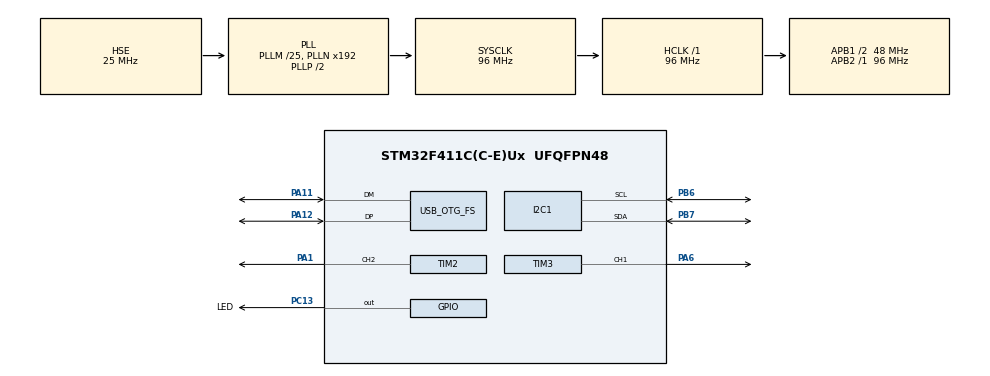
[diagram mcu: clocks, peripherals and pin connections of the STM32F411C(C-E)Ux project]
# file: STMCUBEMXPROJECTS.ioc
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Mcu.Family=STM32F4
Mcu.Name=STM32F411C(C-E)Ux
Mcu.Package=UFQFPN48
NVIC.OTG_FS_IRQn=true\:0\:0\:false\:false\:true\:false\:true\:true
NVIC.PriorityGroup=NVIC_PRIORITYGROUP_4
PA1.Signal=S_TIM2_CH2
PA11.Mode=Device_Only
PA11.Signal=USB_OTG_FS_DM
PA12.Mode=Device_Only
PA12.Signal=USB_OTG_FS_DP
PA13.Mode=Serial_Wire
PA13.Signal=SYS_JTMS-SWDIO
PA14.Mode=Serial_Wire
PA14.Signal=SYS_JTCK-SWCLK
PA6.Signal=S_TIM3_CH1
PB6.Mode=I2C
PB6.Signal=I2C1_SCL
PB7.Mode=I2C
PB7.Signal=I2C1_SDA
PC13-ANTI_TAMP.GPIO_Label=LED
PC13-ANTI_TAMP.Signal=GPIO_Output
PH0\ -\ OSC_IN.Mode=HSE-External-Oscillator
PH0\ -\ OSC_IN.Signal=RCC_OSC_IN
PH1\ -\ OSC_OUT.Mode=HSE-External-Oscillator
PH1\ -\ OSC_OUT.Signal=RCC_OSC_OUT
ProjectManager.HeapSize=0x200
ProjectManager.StackSize=0x400
ProjectManager.TargetToolchain=CMake
RCC.48MHZClocksFreq_Value=48000000
RCC.AHBFreq_Value=96000000
RCC.APB1CLKDivider=RCC_HCLK_DIV2
RCC.APB1Freq_Value=48000000
RCC.APB1TimFreq_Value=96000000
RCC.APB2Freq_Value=96000000
RCC.APB2TimFreq_Value=96000000
RCC.CortexFreq_Value=96000000
RCC.HCLKFreq_Value=96000000
RCC.HSE_VALUE=25000000
RCC.HSI_VALUE=16000000
RCC.LSE_VALUE=32768
RCC.PLLM=25
RCC.SYSCLKFreq_VALUE=96000000
RCC.SYSCLKSource=RCC_SYSCLKSOURCE_PLLCLK
RCC.VCOOutputFreq_Value=192000000
SH.S_TIM2_CH2.0=TIM2_CH2,PWM Generation2 CH2
SH.S_TIM3_CH1.0=TIM3_CH1,PWM Generation1 CH1
TIM2.Channel-PWM\ Generation2\ CH2=TIM_CHANNEL_2
TIM2.Period=19999
TIM2.Prescaler=95
TIM2.Pulse-PWM\ Generation2\ CH2=1500
TIM3.Channel-PWM\ Generation1\ CH1=TIM_CHANNEL_1
TIM3.Period=999
TIM3.Prescaler=95
TIM3.Pulse-PWM\ Generation1\ CH1=250
USB_DEVICE.CLASS_NAME_FS=CDC
USB_DEVICE.VirtualMode=Cdc
USB_DEVICE.VirtualModeFS=Cdc_FS
USB_OTG_FS.VirtualMode=Device_Only
VP_TIM2_VS_ClockSourceINT.Mode=Internal
VP_TIM3_VS_ClockSourceINT.Mode=Internal
VP_USB_DEVICE_VS_USB_DEVICE_CDC_FS.Mode=CDC_FS
board=custom

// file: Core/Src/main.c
/* USER CODE BEGIN Header */
/**
 ******************************************************************************
 * @file           : main.c
 * @brief          : Main program body
 ******************************************************************************
 * @attention
 *
 * Copyright (c) 2026 STMicroelectronics.
 * All rights reserved.
 *
 * This software is licensed under terms that can be found in the LICENSE file
 * in the root directory of this software component.
 * If no LICENSE file comes with this software, it is provided AS-IS.
 *
 ******************************************************************************
 */
/* USER CODE END Header */
#include "main.h"
#include "usb_device.h"

/* USER CODE BEGIN Includes */
#include "app.h"

/* USER CODE END Includes */

I2C_HandleTypeDef hi2c1;

TIM_HandleTypeDef htim2;
TIM_HandleTypeDef htim3;

void SystemClock_Config(void);
static void MX_GPIO_Init(void);
static void MX_TIM3_Init(void);
static void MX_TIM2_Init(void);
static void MX_I2C1_Init(void);

int main(void)
{

  /* MCU Configuration--------------------------------------------------------*/

  /* Reset of all peripherals, Initializes the Flash interface and the Systick. */
  HAL_Init();

  /* Configure the system clock */
  SystemClock_Config();

  /* Initialize all configured peripherals */
  MX_GPIO_Init();
  MX_USB_DEVICE_Init();
  MX_TIM3_Init();
  MX_TIM2_Init();
  MX_I2C1_Init();
  /* USER CODE BEGIN 2 */

  app_setup();

  /* USER CODE END 2 */

  /* Infinite loop */
  while (1) {

    /* USER CODE BEGIN 3 */

    app_loop();
  }
  /* USER CODE END 3 */
}

void SystemClock_Config(void)
{
  RCC_OscInitTypeDef RCC_OscInitStruct = {0};
  RCC_ClkInitTypeDef RCC_ClkInitStruct = {0};

  /** Configure the main internal regulator output voltage
  */
  __HAL_RCC_PWR_CLK_ENABLE();
  __HAL_PWR_VOLTAGESCALING_CONFIG(PWR_REGULATOR_VOLTAGE_SCALE1);

  /** Initializes the RCC Oscillators according to the specified parameters
  * in the RCC_OscInitTypeDef structure.
  */
  RCC_OscInitStruct.OscillatorType = RCC_OSCILLATORTYPE_HSE;
  RCC_OscInitStruct.HSEState = RCC_HSE_ON;
  RCC_OscInitStruct.PLL.PLLState = RCC_PLL_ON;
  RCC_OscInitStruct.PLL.PLLSource = RCC_PLLSOURCE_HSE;
  RCC_OscInitStruct.PLL.PLLM = 25;
  RCC_OscInitStruct.PLL.PLLN = 192;
  RCC_OscInitStruct.PLL.PLLP = RCC_PLLP_DIV2;
  RCC_OscInitStruct.PLL.PLLQ = 4;
  if (HAL_RCC_OscConfig(&RCC_OscInitStruct) != HAL_OK)
  {
    Error_Handler();
  }

  /** Initializes the CPU, AHB and APB buses clocks
  */
  RCC_ClkInitStruct.ClockType = RCC_CLOCKTYPE_HCLK|RCC_CLOCKTYPE_SYSCLK
                              |RCC_CLOCKTYPE_PCLK1|RCC_CLOCKTYPE_PCLK2;
  RCC_ClkInitStruct.SYSCLKSource = RCC_SYSCLKSOURCE_PLLCLK;
  RCC_ClkInitStruct.AHBCLKDivider = RCC_SYSCLK_DIV1;
  RCC_ClkInitStruct.APB1CLKDivider = RCC_HCLK_DIV2;
  RCC_ClkInitStruct.APB2CLKDivider = RCC_HCLK_DIV1;

  if (HAL_RCC_ClockConfig(&RCC_ClkInitStruct, FLASH_LATENCY_3) != HAL_OK)
  {
    Error_Handler();
  }
}

static void MX_I2C1_Init(void)
{

  hi2c1.Instance = I2C1;
  hi2c1.Init.ClockSpeed = 100000;
  hi2c1.Init.DutyCycle = I2C_DUTYCYCLE_2;
  hi2c1.Init.OwnAddress1 = 0;
  hi2c1.Init.AddressingMode = I2C_ADDRESSINGMODE_7BIT;
  hi2c1.Init.DualAddressMode = I2C_DUALADDRESS_DISABLE;
  hi2c1.Init.OwnAddress2 = 0;
  hi2c1.Init.GeneralCallMode = I2C_GENERALCALL_DISABLE;
  hi2c1.Init.NoStretchMode = I2C_NOSTRETCH_DISABLE;
  if (HAL_I2C_Init(&hi2c1) != HAL_OK)
  {
    Error_Handler();
  }

}

static void MX_TIM2_Init(void)
{

  TIM_ClockConfigTypeDef sClockSourceConfig = {0};
  TIM_MasterConfigTypeDef sMasterConfig = {0};
  TIM_OC_InitTypeDef sConfigOC = {0};

  htim2.Instance = TIM2;
  htim2.Init.Prescaler = 95;
  htim2.Init.CounterMode = TIM_COUNTERMODE_UP;
  htim2.Init.Period = 19999;
  htim2.Init.ClockDivision = TIM_CLOCKDIVISION_DIV1;
  htim2.Init.AutoReloadPreload = TIM_AUTORELOAD_PRELOAD_DISABLE;
  if (HAL_TIM_Base_Init(&htim2) != HAL_OK)
  {
    Error_Handler();
  }
  sClockSourceConfig.ClockSource = TIM_CLOCKSOURCE_INTERNAL;
  if (HAL_TIM_ConfigClockSource(&htim2, &sClockSourceConfig) != HAL_OK)
  {
    Error_Handler();
  }
  if (HAL_TIM_PWM_Init(&htim2) != HAL_OK)
  {
    Error_Handler();
  }
  sMasterConfig.MasterOutputTrigger = TIM_TRGO_RESET;
  sMasterConfig.MasterSlaveMode = TIM_MASTERSLAVEMODE_DISABLE;
  if (HAL_TIMEx_MasterConfigSynchronization(&htim2, &sMasterConfig) != HAL_OK)
  {
    Error_Handler();
  }
  sConfigOC.OCMode = TIM_OCMODE_PWM1;
  sConfigOC.Pulse = 1500;
  sConfigOC.OCPolarity = TIM_OCPOLARITY_HIGH;
  sConfigOC.OCFastMode = TIM_OCFAST_DISABLE;
  if (HAL_TIM_PWM_ConfigChannel(&htim2, &sConfigOC, TIM_CHANNEL_2) != HAL_OK)
  {
    Error_Handler();
  }
  HAL_TIM_MspPostInit(&htim2);

}

static void MX_TIM3_Init(void)
{

  TIM_ClockConfigTypeDef sClockSourceConfig = {0};
  TIM_MasterConfigTypeDef sMasterConfig = {0};
  TIM_OC_InitTypeDef sConfigOC = {0};

  htim3.Instance = TIM3;
  htim3.Init.Prescaler = 95;
  htim3.Init.CounterMode = TIM_COUNTERMODE_UP;
  htim3.Init.Period = 999;
  htim3.Init.ClockDivision = TIM_CLOCKDIVISION_DIV1;
  htim3.Init.AutoReloadPreload = TIM_AUTORELOAD_PRELOAD_DISABLE;
  if (HAL_TIM_Base_Init(&htim3) != HAL_OK)
  {
    Error_Handler();
  }
  sClockSourceConfig.ClockSource = TIM_CLOCKSOURCE_INTERNAL;
  if (HAL_TIM_ConfigClockSource(&htim3, &sClockSourceConfig) != HAL_OK)
  {
    Error_Handler();
  }
  if (HAL_TIM_PWM_Init(&htim3) != HAL_OK)
  {
    Error_Handler();
  }
  sMasterConfig.MasterOutputTrigger = TIM_TRGO_RESET;
  sMasterConfig.MasterSlaveMode = TIM_MASTERSLAVEMODE_DISABLE;
  if (HAL_TIMEx_MasterConfigSynchronization(&htim3, &sMasterConfig) != HAL_OK)
  {
    Error_Handler();
  }
  sConfigOC.OCMode = TIM_OCMODE_PWM1;
  sConfigOC.Pulse = 250;
  sConfigOC.OCPolarity = TIM_OCPOLARITY_HIGH;
  sConfigOC.OCFastMode = TIM_OCFAST_DISABLE;
  if (HAL_TIM_PWM_ConfigChannel(&htim3, &sConfigOC, TIM_CHANNEL_1) != HAL_OK)
  {
    Error_Handler();
  }
  HAL_TIM_MspPostInit(&htim3);

}

static void MX_GPIO_Init(void)
{
  GPIO_InitTypeDef GPIO_InitStruct = {0};

  /* GPIO Ports Clock Enable */
  __HAL_RCC_GPIOC_CLK_ENABLE();
  __HAL_RCC_GPIOH_CLK_ENABLE();
  __HAL_RCC_GPIOA_CLK_ENABLE();
  __HAL_RCC_GPIOB_CLK_ENABLE();

  /*Configure GPIO pin Output Level */
  HAL_GPIO_WritePin(LED_GPIO_Port, LED_Pin, GPIO_PIN_RESET);

  /*Configure GPIO pin : LED_Pin */
  GPIO_InitStruct.Pin = LED_Pin;
  GPIO_InitStruct.Mode = GPIO_MODE_OUTPUT_PP;
  GPIO_InitStruct.Pull = GPIO_NOPULL;
  GPIO_InitStruct.Speed = GPIO_SPEED_FREQ_LOW;
  HAL_GPIO_Init(LED_GPIO_Port, &GPIO_InitStruct);

}

void Error_Handler(void)
{
  __disable_irq();
  while (1) {
  }
}
#ifdef USE_FULL_ASSERT
/**
  * @brief  Reports the name of the source file and the source line number
  *         where the assert_param error has occurred.
  * @param  file: pointer to the source file name
  * @param  line: assert_param error line source number
  * @retval None
  */
void assert_failed(uint8_t *file, uint32_t line)
{
  /* USER CODE BEGIN 6 */
  /* User can add his own implementation to report the file name and line
     number, ex: printf("Wrong parameters value: file %s on line %d\r\n", file,
     line) */
  /* USER CODE END 6 */
}
#endif /* USE_FULL_ASSERT */
